# SN32F100 register map
Vendor: SONiX Technology Co., Ltd.; Series: SN32F100; File version: 1.3
CPU: CM0 r0p0, little endian, no MPU, no FPU, 2 interrupt priority bits
Registers are 32-bit, read-write, reset 0x0 unless marked. A register's access mark holds for its fields unless they carry their own. Offsets are from the block's base; [hi:lo] are bit positions; {n}, {i} and the like mark numbered series; 'fields as' and 'values as' point back to an identical list.

## SN_SYS1 — System Control Registers
Base 0x4005E000
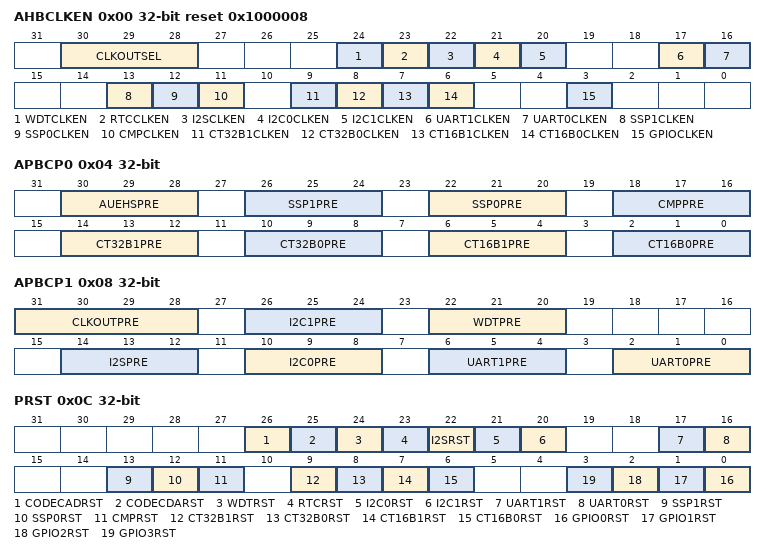
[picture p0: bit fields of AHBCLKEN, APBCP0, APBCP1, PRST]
0x00 AHBCLKEN reset 0x1000008 — Offset:0x00 AHB Clock Enable Register
  [30:28] CLKOUTSEL — Clock output source selection
    0=000b (Disable); 1=001b (HCLK clock output); 2=010b (PLL clock output); 3=011b (ILRC clock output); 4=100b (IHRC clock output); 5=101b (ELS clock output); 6=110b (EHS XTAL); 7=111b (AUEHS XTAL)
  [24] WDTCLKEN — Enable AHB clock for WDT
    0=Disable; 1=Enable
  [23] RTCCLKEN — Enable AHB clock for RTC
    0=Disable; 1=Enable
  [22] I2SCLKEN — Enable AHB clock for I2S
    0=Disable; 1=Enable
  [21] I2C0CLKEN — Enable AHB clock for I2C0
    0=Disable; 1=Enable
  [20] I2C1CLKEN — Enable AHB clock for I2C1
    0=Disable; 1=Enable
  [17] UART1CLKEN — Enable AHB clock for UART1
    0=Disable; 1=Enable
  [16] UART0CLKEN — Enable AHB clock for UART0
    0=Disable; 1=Enable
  [13] SSP1CLKEN — Enable AHB clock for SSP1
    0=Disable; 1=Enable
  [12] SSP0CLKEN — Enable AHB clock for SSP0
    0=Disable; 1=Enable
  [11] CMPCLKEN — Enable AHB clock for Comparator
    0=Disable; 1=Enable
  [9] CT32B1CLKEN — Enable AHB clock for CT32B1
    0=Disable; 1=Enable
  [8] CT32B0CLKEN — Enable AHB clock for CT32B0
    0=Disable; 1=Enable
  [7] CT16B1CLKEN — Enable AHB clock for CT16B1
    0=Disable; 1=Enable
  [6] CT16B0CLKEN — Enable AHB clock for CT16B0
    0=Disable; 1=Enable
  [3] GPIOCLKEN — Enable AHB clock for GPIO
    0=Disable; 1=Enable
0x04 APBCP0 — Offset:0x04 APB Clock Prescale Register 0
  [30:28] AUEHSPRE — Audio external high clock source prescaler
    0=000b (HCLK/1); 1=001b (HCLK/2); 2=010b (HCLK/4); 3=011b (HCLK/8); 4=100b (HCLK/16)
  [26:24] SSP1PRE — SSP1 APB clock source prescaler
    values as AUEHSPRE
  [22:20] SSP0PRE — SSP0 APB clock source prescaler
    values as AUEHSPRE
  [18:16] CMPPRE — Comparator clock source prescaler
    values as AUEHSPRE
  [14:12] CT32B1PRE — CT32B1 APB clock source prescaler
    values as AUEHSPRE
  [10:8] CT32B0PRE — CT32B0 APB clock source prescaler
    values as AUEHSPRE
  [6:4] CT16B1PRE — CT16B1 APB clock source prescaler
    0=000b (HCLK/1); 1=001b (HCLK/2); 2=010b (HCLK/4); 3=HCLK/8; 4=HCLK/16
  [2:0] CT16B0PRE — CT16B0 APB clock source prescaler
    values as AUEHSPRE
0x08 APBCP1 — Offset:0x08 APB Clock Prescale Register 1
  [31:28] CLKOUTPRE — CLKOUT APB clock source prescaler
    0=0000b (FCLKOUT/1); 1=0001b (FCLKOUT/2); 2=0010b (FCLKOUT/4); 3=0011b (FCLKOUT/8); 4=0100b (FCLKOUT/16); 5=0101b (FCLKOUT/32); 6=0110b (FCLKOUT/64); 7=0111b (FCLKOUT/128); 8=1000b (FCLKOUT/256); 9=1001b (FCLKOUT/512)
  [26:24] I2C1PRE — I2C1 APB clock source prescaler
    values as APBCP0.AUEHSPRE
  [22:20] WDTPRE — WDT APB clock source prescaler
    0=000b (HCLK/1); 1=001b (HCLK/2); 2=010b (HCLK/4); 3=011b (HCLK/8); 4=100b (HCLK/16); 5=101b (HCLK/32)
  [14:12] I2SPRE — I2S APB clock source prescaler
    values as APBCP0.AUEHSPRE
  [10:8] I2C0PRE — I2C0 APB clock source prescaler
    values as APBCP0.AUEHSPRE
  [6:4] UART1PRE — UART1 APB clock source prescaler
    values as APBCP0.AUEHSPRE
  [2:0] UART0PRE — UART0 APB clock source prescaler
    values as APBCP0.AUEHSPRE
0x0C PRST — Offset:0x0C Peripheral Reset Register
  [26] CODECADRST — Codec ADC reset
    0=No effect; 1=Reset WDT
  [25] CODECDARST — Codec DAC reset
    0=No effect; 1=Reset WDT
  [24] WDTRST — WDT Reset
    0=No effect; 1=Reset WDT
  [23] RTCRST — RTC Reset
    0=No effect; 1=Reset RTC
  [22] I2SRST — I2S Reset
    0=No effect; 1=Reset I2S
  [21] I2C0RST — I2C0 Reset
    0=No effect; 1=Reset I2C0
  [20] I2C1RST — I2C1 Reset
    0=No effect; 1=Reset I2C1
  [17] UART1RST — UART1 Reset
    0=No effect; 1=Reset UART1
  [16] UART0RST — UART0 Reset
    0=No effect; 1=Reset UART0
  [13] SSP1RST — SSP1 Reset
    0=No effect; 1=Reset SSP1
  [12] SSP0RST — SSP0 Reset
    0=No effect; 1=Reset SSP0
  [11] CMPRST — Comparator Reset
    0=No effect; 1=Reset CMP
  [9] CT32B1RST — CT32B1 Reset
    0=No effect; 1=Reset CT32B1
  [8] CT32B0RST — CT32B0 Reset
    0=No effect; 1=Reset CT32B0
  [7] CT16B1RST — CT16B1 Reset
    0=No effect; 1=Reset CT16B1
  [6] CT16B0RST — CT16B0 Reset
    0=No effect; 1=Reset CT16B0
  [n] GPIO{n}RST (n=0..3) — GPIO{n} Reset
    0=No effect; 1=Reset GPIO{n}
